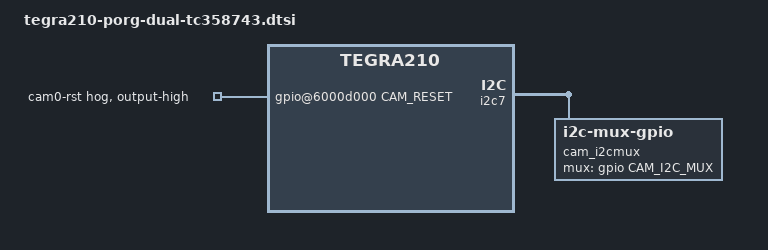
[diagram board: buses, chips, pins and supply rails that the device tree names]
#include "tegra210-dual-tc358743.dtsi"

#define CAM_I2C_MUX TEGRA_GPIO(I, 0) // NFC_EN GPIO
#define CAM_RESET TEGRA_GPIO(Z, 0) 
/ {
	cam_i2cmux {
		compatible = "i2c-mux-gpio";
		#address-cells = <1>;
		#size-cells = <0>;
		mux-gpios = <&gpio CAM_I2C_MUX GPIO_ACTIVE_HIGH>;
		i2c-parent = <&i2c7>;
		i2c@0 {
			reg = <0>;
			#address-cells = <1>;
			#size-cells = <0>;

		};
		i2c@1 {
			reg = <1>;
			#address-cells = <1>;
			#size-cells = <0>;
		};

	};

	gpio@6000d000 {
		camera-control-output-high {
			gpio-hog;
			output-high;
			gpios = < CAM_RESET 0>;
			label = "cam0-rst";
		};
	};

};
